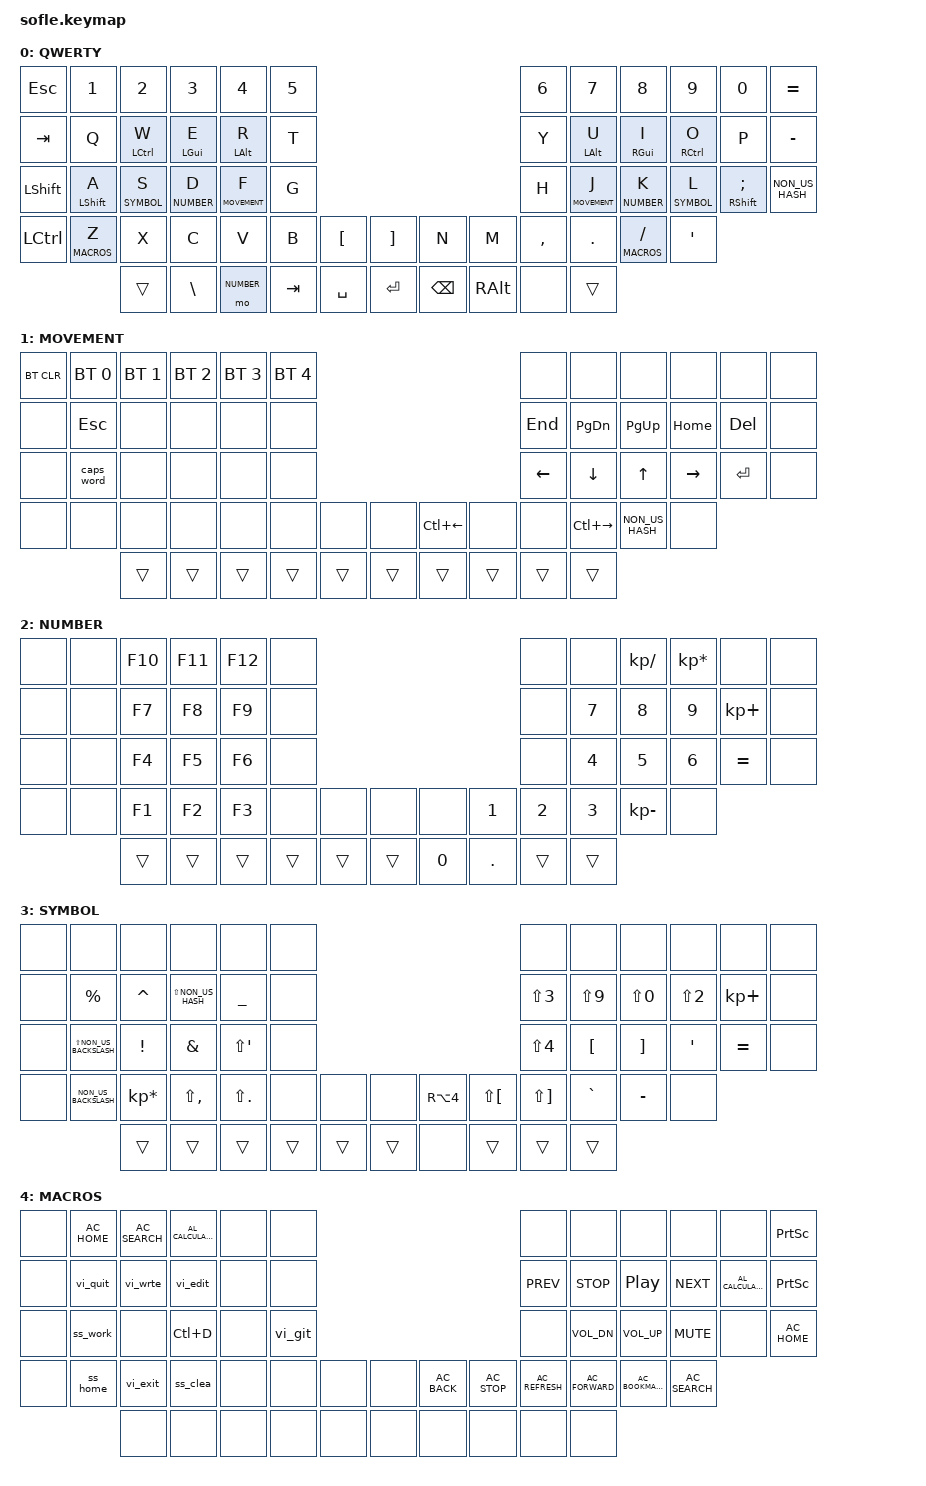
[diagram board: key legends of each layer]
/*
 * Ported from QMK keymaps/lily58/keymaps/kat/keymap.c (Miryoku-style: home
 * row mods on the letter row, layer-taps on the home row, dedicated macros
 * layer). Filled out to the Sofle's extra row/thumb keys using the same
 * author's mechboards/sofle/pro/keymaps/kat/keymap.c, since that's sized for
 * the identical physical board.
 *
 * Position indices (used by the hold-tap trigger lists below):
 *   0  1  2  3  4  5     6  7  8  9 10 11
 *  12 13 14 15 16 17    18 19 20 21 22 23
 *  24 25 26 27 28 29    30 31 32 33 34 35
 *  36 37 38 39 40 41 42 43 44 45 46 47 48 49
 *        50 51 52 53 54 55 56 57 58 59
 */

#include <behaviors.dtsi>
#include <dt-bindings/zmk/keys.h>
#include <dt-bindings/zmk/bt.h>
#include <dt-bindings/zmk/rgb.h>
#include <dt-bindings/zmk/ext_power.h>

// This adapter's SPI chip-select is wired to pro_micro pin 4, not the
// nice_view_adapter shield's default of pin 1 (per Mechboards' own
// zmk-config for this board: MechboardsLTD/zmk-config@refresh_mips).
&nice_view_spi {
    cs-gpios = <&pro_micro 4 GPIO_ACTIVE_HIGH>;
};

#define QWERTY   0
#define MOVEMENT 1
#define NUMBER   2
#define SYMBOL   3
#define MACROS   4

/ {
    behaviors {
        // mod-tap for LEFT-hand keys (W E R, A) - only "holds" if a RIGHT-hand
        // key is pressed while held, so same-hand rolls don't misfire.
        hml: homerow_mods_left {
            compatible = "zmk,behavior-hold-tap";
            #binding-cells = <2>;
            flavor = "balanced";
            tapping-term-ms = <280>;
            quick-tap-ms = <175>;
            require-prior-idle-ms = <150>;
            bindings = <&kp>, <&kp>;
            hold-trigger-key-positions = <6 7 8 9 10 11 18 19 20 21 22 23 30 31 32 33 34 35 43 44 45 46 47 48 49 55 56 57 58 59>;
            hold-trigger-on-release;
        };

        // mod-tap for RIGHT-hand keys (U I O, ;) - triggers off LEFT-hand keys.
        hmr: homerow_mods_right {
            compatible = "zmk,behavior-hold-tap";
            #binding-cells = <2>;
            flavor = "balanced";
            tapping-term-ms = <280>;
            quick-tap-ms = <175>;
            require-prior-idle-ms = <150>;
            bindings = <&kp>, <&kp>;
            hold-trigger-key-positions = <0 1 2 3 4 5 12 13 14 15 16 17 24 25 26 27 28 29 36 37 38 39 40 41 42 50 51 52 53 54>;
            hold-trigger-on-release;
        };

        // layer-tap used on S D F / J K L / Z / (the SYMBOL, NUMBER, MOVEMENT,
        // MACROS layer-taps). tap-preferred so normal typing doesn't trigger
        // the layer.
        lh: layer_hold_tap {
            compatible = "zmk,behavior-hold-tap";
            #binding-cells = <2>;
            flavor = "tap-preferred";
            tapping-term-ms = <200>;
            bindings = <&mo>, <&kp>;
        };
    };

    macros {
        vi_wrte: vi_wrte_macro {
            compatible = "zmk,behavior-macro";
            #binding-cells = <0>;
            bindings = <&kp ESC &kp COLON &kp W &kp RET>;
        };

        vi_edit: vi_edit_macro {
            compatible = "zmk,behavior-macro";
            #binding-cells = <0>;
            bindings = <&kp ESC &kp COLON &kp E &kp RET>;
        };

        vi_quit: vi_quit_macro {
            compatible = "zmk,behavior-macro";
            #binding-cells = <0>;
            bindings = <&kp ESC &kp COLON &kp Q &kp RET>;
        };

        vi_exit: vi_exit_macro {
            compatible = "zmk,behavior-macro";
            #binding-cells = <0>;
            bindings = <&kp ESC &kp COLON &kp X &kp RET>;
        };

        vi_git: vi_git_macro {
            compatible = "zmk,behavior-macro";
            #binding-cells = <0>;
            bindings = <&kp ESC &kp COLON &kp LS(G) &kp I &kp T &kp SPACE>;
        };

        ss_clea: ss_clea_macro {
            compatible = "zmk,behavior-macro";
            #binding-cells = <0>;
            bindings = <&kp RET &kp C &kp L &kp E &kp A &kp R &kp RET>;
        };

        // NOTE: the original QMK macro sent Shift+Quote for the "@" - a UK
        // ISO-layout trick (shift+' = @ on UK, but = " on US). Kept identical
        // here so behaviour matches on your UK host. If your host is US
        // layout instead, swap &kp LS(SQT) for &kp AT.
        ss_home: ss_home_macro {
            compatible = "zmk,behavior-macro";
            #binding-cells = <0>;
            bindings = <&kp K &kp A &kp T &kp LS(SQT) &kp C &kp R &kp I &kp C &kp H &kp T &kp O &kp N &kp MINUS &kp S &kp E &kp A &kp G &kp E &kp R &kp DOT &kp C &kp O &kp M>;
        };

        ss_work: ss_work_macro {
            compatible = "zmk,behavior-macro";
            #binding-cells = <0>;
            bindings = <&kp K &kp A &kp T &kp LS(SQT) &kp C &kp L &kp I &kp C &kp K &kp M &kp E &kp C &kp H &kp A &kp N &kp I &kp C &kp DOT &kp C &kp O &kp M>;
        };
    };

    keymap {
        compatible = "zmk,keymap";

        qwerty_layer {
            display-name = "QWERTY";
// ------------------------------------------------------------------------------------------------------------
// | ESC  |  1  |  2  |  3  |  4  |  5  |                | 6  |  7   |  8   |  9  |  0  |  =  |
// | TAB  |  Q  | Wc  | Eg  | Ra  |  T  |                | Y  | Ua   | Ig   | Oc  |  P  |  -  |
// |SHIFT | As  |Ssym |Dnum |Fmov |  G  |                | H  |Jmov  |Knum  |Lsym | ;s  | NUHS|
// |CTRL  |Zmac |  X  |  C  |  V  |  B  | [  |  ]        | N  |  M   |  ,   |  .  |/mac | '   |
//              trans | \   |MO(N)| TAB |SPC | ENT | BSPC| RALT| none| trans
            bindings = <
&kp ESC     &kp N1        &kp N2        &kp N3        &kp N4        &kp N5                                        &kp N6  &kp N7        &kp N8        &kp N9        &kp N0     &kp EQUAL
&kp TAB     &kp Q         &hml LCTRL W  &hml LGUI E   &hml LALT R   &kp T                                         &kp Y   &hmr LALT U   &hmr RGUI I   &hmr RCTRL O  &kp P      &kp MINUS
&kp LSHFT   &hml LSHFT A  &lh SYMBOL S  &lh NUMBER D  &lh MOVEMENT F&kp G                                         &kp H   &lh MOVEMENT J&lh NUMBER K  &lh SYMBOL L  &hmr RSHFT SEMI &kp NON_US_HASH
&kp LCTRL   &lh MACROS Z  &kp X         &kp C         &kp V         &kp B    &kp LBKT  &kp RBKT   &kp N   &kp M         &kp COMMA     &kp DOT       &lh MACROS FSLH &kp SQT
                          &trans        &kp BSLH      &mo NUMBER    &kp TAB  &kp SPACE &kp RET    &kp BSPC &kp RALT     &none         &trans
            >;

            sensor-bindings = <&inc_dec_kp C_VOL_DN C_VOL_UP &inc_dec_kp C_PREV C_NEXT>;
        };

        movement_layer {
            display-name = "MOVEMENT";
            bindings = <
&bt BT_CLR &bt BT_SEL 0 &bt BT_SEL 1  &bt BT_SEL 2  &bt BT_SEL 3  &bt BT_SEL 4                    &none     &none     &none    &none      &none   &none
&none      &kp ESC  &none  &none  &none  &none                    &kp END  &kp PG_DN &kp PG_UP&kp HOME    &kp DEL &none
&none      &caps_word &none &none &none  &none                    &kp LEFT  &kp DOWN  &kp UP   &kp RIGHT  &kp RET &none
&none      &none    &none  &none  &none  &none  &none  &none      &kp LC(LEFT) &none  &none    &kp LC(RIGHT) &kp NON_US_HASH &none
                &trans &trans &trans &trans &trans &trans     &trans    &trans    &trans   &trans
            >;
        };

        number_layer {
            display-name = "NUMBER";
            bindings = <
&none  &none  &kp F10 &kp F11 &kp F12 &none                    &none  &none    &kp KP_DIVIDE  &kp KP_MULTIPLY &none  &none
&none  &none  &kp F7  &kp F8  &kp F9  &none                    &none  &kp N7   &kp N8         &kp N9          &kp KP_PLUS &none
&none  &none  &kp F4  &kp F5  &kp F6  &none                    &none  &kp N4   &kp N5         &kp N6          &kp EQUAL  &none
&none  &none  &kp F1  &kp F2  &kp F3  &none  &none  &none      &none  &kp N1   &kp N2         &kp N3          &kp KP_MINUS &none
              &trans  &trans  &trans  &trans &trans &trans     &kp N0 &kp DOT  &trans         &trans
            >;
        };

        symbol_layer {
            display-name = "SYMBOL";
            bindings = <
&none  &none      &none      &none        &none      &none                                &none         &none        &none        &none        &none        &none
&none  &kp PRCNT  &kp CARET  &kp LS(NON_US_HASH) &kp UNDER &none                            &kp LS(N3)    &kp LS(N9)   &kp LS(N0)   &kp LS(N2)   &kp KP_PLUS  &none
&none  &kp LS(NON_US_BACKSLASH) &kp EXCL &kp AMPS &kp LS(SQT) &none                          &kp LS(N4)    &kp LBKT     &kp RBKT     &kp SQT      &kp EQUAL    &none
&none  &kp NON_US_BACKSLASH &kp KP_MULTIPLY &kp LS(COMMA) &kp LS(DOT) &none  &none  &none    &kp RA(N4)  &kp LS(LBKT) &kp LS(RBKT) &kp GRAVE    &kp MINUS    &none
                   &trans     &trans       &trans     &trans     &trans     &trans     &none            &trans       &trans       &trans
            >;
        };

        macros_layer {
            display-name = "MACROS";
            bindings = <
&none  &kp C_AC_HOME &kp C_AC_SEARCH &kp C_AL_CALCULATOR &none &none                        &none      &none      &none      &none      &none      &kp PSCRN
&none  &vi_quit      &vi_wrte        &vi_edit            &none &none                        &kp C_PREV &kp C_STOP &kp C_PP   &kp C_NEXT &kp C_AL_CALCULATOR &kp PSCRN
&none  &ss_work      &none           &kp LC(D)           &none &vi_git                      &none      &kp C_VOL_DN &kp C_VOL_UP &kp C_MUTE &none    &kp C_AC_HOME
&none  &ss_home      &vi_exit        &ss_clea            &none &none  &none  &none          &kp C_AC_BACK &kp C_AC_STOP &kp C_AC_REFRESH &kp C_AC_FORWARD &kp C_AC_BOOKMARKS &kp C_AC_SEARCH
                     &none           &none               &none &none  &none  &none          &none      &none      &none      &none
            >;
        };
    };
};
